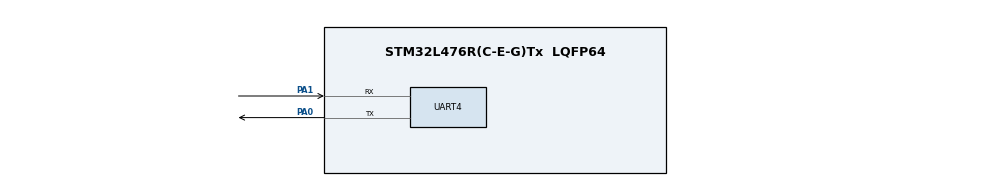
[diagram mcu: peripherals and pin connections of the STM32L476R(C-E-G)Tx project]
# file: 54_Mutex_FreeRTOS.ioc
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FREERTOS.Tasks01=defaultTask,24,128,StartDefaultTask,Default,NULL,Dynamic,NULL,NULL
Mcu.Family=STM32L4
Mcu.Name=STM32L476R(C-E-G)Tx
Mcu.Package=LQFP64
NVIC.PriorityGroup=NVIC_PRIORITYGROUP_4
PA0.Mode=Asynchronous
PA0.Signal=UART4_TX
PA1.Mode=Asynchronous
PA1.Signal=UART4_RX
ProjectManager.HeapSize=0x200
ProjectManager.StackSize=0x400
ProjectManager.TargetToolchain=STM32CubeIDE
RCC.HSE_VALUE=8000000
RCC.HSI_VALUE=16000000
RCC.LSE_VALUE=32768
RCC.MSI_VALUE=4000000
RCC.VCOOutputFreq_Value=32000000
VP_FREERTOS_VS_CMSIS_V2.Mode=CMSIS_V2
board=custom

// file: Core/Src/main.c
/* USER CODE BEGIN Header */
/**
  ******************************************************************************
  * @file           : main.c
  * @brief          : Main program body
  ******************************************************************************
  * @attention
  *
  * Copyright (c) 2026 STMicroelectronics.
  * All rights reserved.
  *
  * This software is licensed under terms that can be found in the LICENSE file
  * in the root directory of this software component.
  * If no LICENSE file comes with this software, it is provided AS-IS.
  *
  ******************************************************************************
  */
/* USER CODE END Header */
#include "main.h"
#include "cmsis_os.h"

/* USER CODE BEGIN Includes */
#include "main.h"
#include "FreeRTOS.h"
#include "task.h"
#include "queue.h"
#include "semphr.h"
#include <string.h>
/* USER CODE END Includes */

UART_HandleTypeDef huart4;

/* Definitions for defaultTask */
osThreadId_t defaultTaskHandle;
const osThreadAttr_t defaultTask_attributes = {
  .name = "defaultTask",
  .stack_size = 128 * 4,
  .priority = (osPriority_t) osPriorityNormal,
};
/* USER CODE BEGIN PV */
SemaphoreHandle_t xUartMutex;
/* USER CODE END PV */

void SystemClock_Config(void);
static void MX_GPIO_Init(void);
static void MX_UART4_Init(void);
void StartDefaultTask(void *argument);

/* USER CODE BEGIN PFP */
void Task1(void *arg);
void Task2(void *arg);

/* USER CODE END PFP */

int main(void)
{

  /* MCU Configuration--------------------------------------------------------*/

  /* Reset of all peripherals, Initializes the Flash interface and the Systick. */
  HAL_Init();

  /* Configure the system clock */
  SystemClock_Config();

  /* Initialize all configured peripherals */
  MX_GPIO_Init();
  MX_UART4_Init();

  /* Init scheduler */
  osKernelInitialize();

  /* Create the thread(s) */
  /* creation of defaultTask */
  defaultTaskHandle = osThreadNew(StartDefaultTask, NULL, &defaultTask_attributes);

  /* USER CODE BEGIN RTOS_THREADS */
  /* add threads, ... */
  xUartMutex = xSemaphoreCreateMutex();

  xTaskCreate(Task1, "Task1", 128, NULL, 2, NULL);
  xTaskCreate(Task2, "Task2", 128, NULL, 2, NULL);
  /* USER CODE END RTOS_THREADS */

  /* Start scheduler */
  osKernelStart();

  /* We should never get here as control is now taken by the scheduler */

  /* Infinite loop */
  while (1)
  {

  }
}

void SystemClock_Config(void)
{
  RCC_OscInitTypeDef RCC_OscInitStruct = {0};
  RCC_ClkInitTypeDef RCC_ClkInitStruct = {0};

  /** Configure the main internal regulator output voltage
  */
  if (HAL_PWREx_ControlVoltageScaling(PWR_REGULATOR_VOLTAGE_SCALE1) != HAL_OK)
  {
    Error_Handler();
  }

  /** Initializes the RCC Oscillators according to the specified parameters
  * in the RCC_OscInitTypeDef structure.
  */
  RCC_OscInitStruct.OscillatorType = RCC_OSCILLATORTYPE_MSI;
  RCC_OscInitStruct.MSIState = RCC_MSI_ON;
  RCC_OscInitStruct.MSICalibrationValue = 0;
  RCC_OscInitStruct.MSIClockRange = RCC_MSIRANGE_6;
  RCC_OscInitStruct.PLL.PLLState = RCC_PLL_NONE;
  if (HAL_RCC_OscConfig(&RCC_OscInitStruct) != HAL_OK)
  {
    Error_Handler();
  }

  /** Initializes the CPU, AHB and APB buses clocks
  */
  RCC_ClkInitStruct.ClockType = RCC_CLOCKTYPE_HCLK|RCC_CLOCKTYPE_SYSCLK
                              |RCC_CLOCKTYPE_PCLK1|RCC_CLOCKTYPE_PCLK2;
  RCC_ClkInitStruct.SYSCLKSource = RCC_SYSCLKSOURCE_MSI;
  RCC_ClkInitStruct.AHBCLKDivider = RCC_SYSCLK_DIV1;
  RCC_ClkInitStruct.APB1CLKDivider = RCC_HCLK_DIV1;
  RCC_ClkInitStruct.APB2CLKDivider = RCC_HCLK_DIV1;

  if (HAL_RCC_ClockConfig(&RCC_ClkInitStruct, FLASH_LATENCY_0) != HAL_OK)
  {
    Error_Handler();
  }
}

static void MX_UART4_Init(void)
{

  huart4.Instance = UART4;
  huart4.Init.BaudRate = 115200;
  huart4.Init.WordLength = UART_WORDLENGTH_8B;
  huart4.Init.StopBits = UART_STOPBITS_1;
  huart4.Init.Parity = UART_PARITY_NONE;
  huart4.Init.Mode = UART_MODE_TX_RX;
  huart4.Init.HwFlowCtl = UART_HWCONTROL_NONE;
  huart4.Init.OverSampling = UART_OVERSAMPLING_16;
  huart4.Init.OneBitSampling = UART_ONE_BIT_SAMPLE_DISABLE;
  huart4.AdvancedInit.AdvFeatureInit = UART_ADVFEATURE_NO_INIT;
  if (HAL_UART_Init(&huart4) != HAL_OK)
  {
    Error_Handler();
  }

}

static void MX_GPIO_Init(void)
{

  /* GPIO Ports Clock Enable */
  __HAL_RCC_GPIOA_CLK_ENABLE();

}

/* USER CODE BEGIN 4 */
void Task1(void *arg)
{
    while(1)
    {
        xSemaphoreTake(xUartMutex, portMAX_DELAY);

        HAL_UART_Transmit(&huart4,
                         (uint8_t*)"Task1 using UART4\r\n",
                         strlen("Task1 using UART4\r\n"),
                         HAL_MAX_DELAY);

        vTaskDelay(pdMS_TO_TICKS(3000));

        xSemaphoreGive(xUartMutex);

        vTaskDelay(pdMS_TO_TICKS(1000));
    }
}

void Task2(void *arg)
{
    while(1)
    {
        xSemaphoreTake(xUartMutex, portMAX_DELAY);

        HAL_UART_Transmit(&huart4,
                         (uint8_t*)"Task2 using UART4\r\n",
                         strlen("Task2 using UART4\r\n"),
                         HAL_MAX_DELAY);

        vTaskDelay(pdMS_TO_TICKS(3000));

        xSemaphoreGive(xUartMutex);

        vTaskDelay(pdMS_TO_TICKS(1000));
    }
}

/* USER CODE END 4 */

void StartDefaultTask(void *argument)
{
  for(;;)
  {
    osDelay(1);
  }
}

void Error_Handler(void)
{
  __disable_irq();
  while (1)
  {
  }
}
